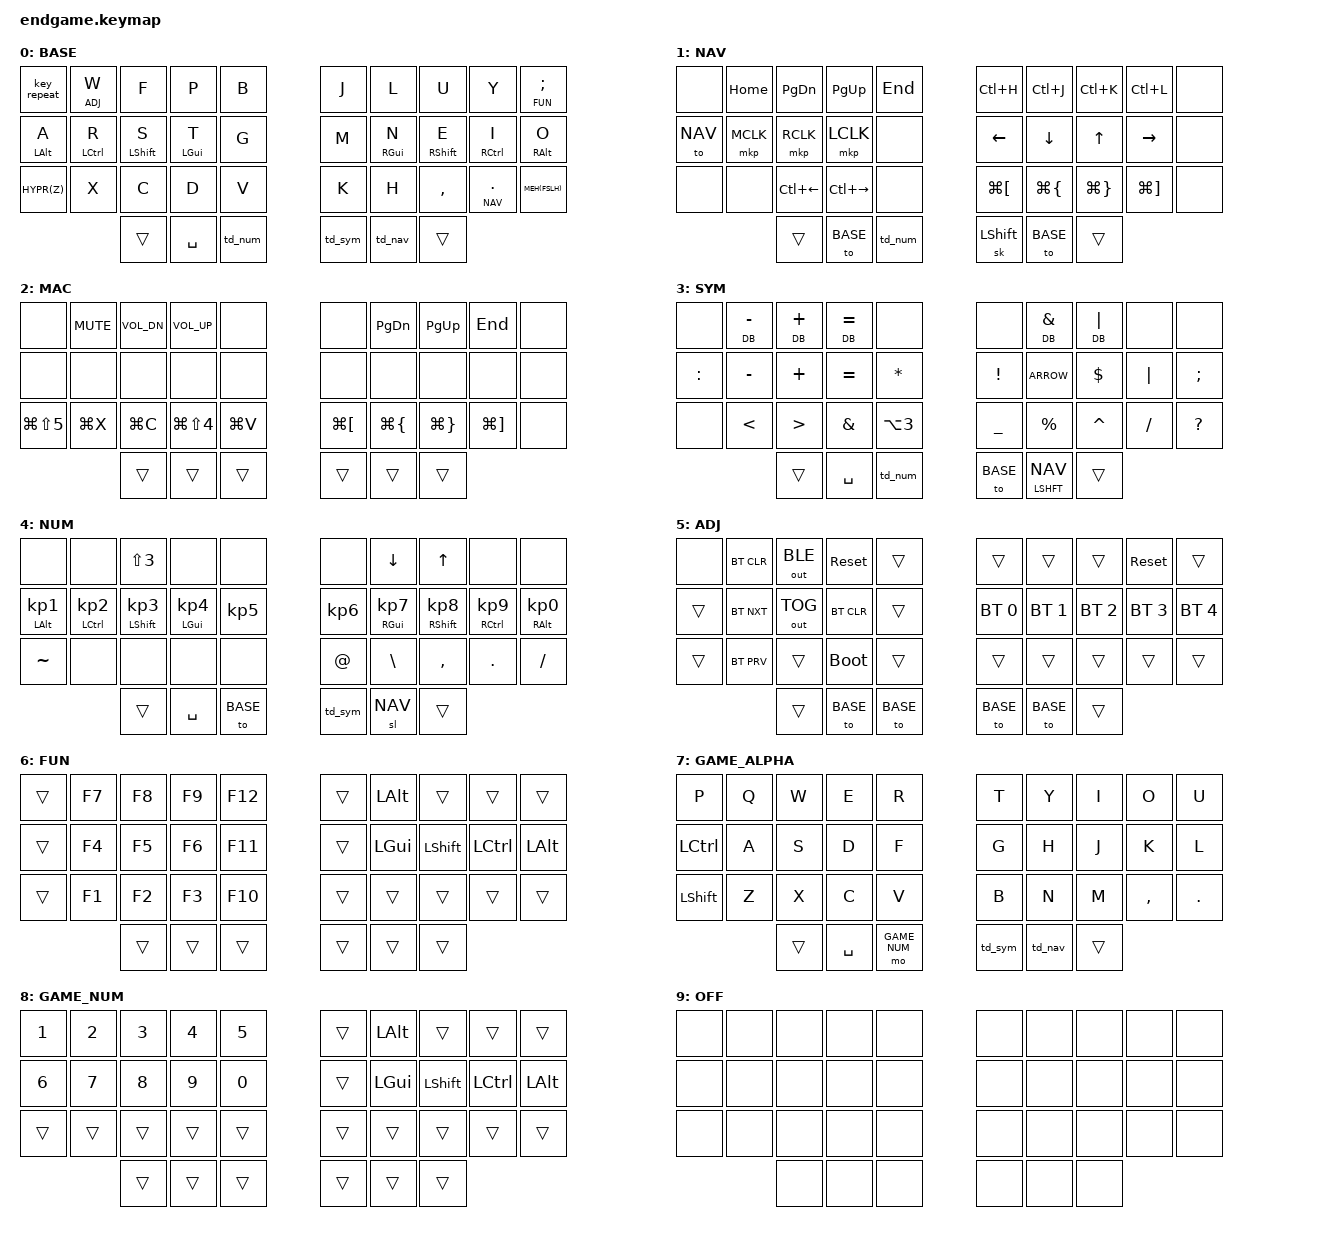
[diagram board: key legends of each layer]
#include <behaviors.dtsi>
#include <dt-bindings/zmk/keys.h>
#include <dt-bindings/zmk/bt.h>
#include <dt-bindings/zmk/outputs.h>
#include <dt-bindings/zmk/pointing.h>
#include <dt-bindings/zmk/ext_power.h>


  /**
   * Combos configuration: only on base layer.
   *
   * Combo key positions:
   *
   *    0  1  2  3  4    5  6  7  8  9
   *   10 11 12 13 14    15 16 17 18 19
   *   20 21 22 23 24    25 26 27 28 29
   *         30 31 32    33 34
   */




#define BASE 0
#define NAV  1
#define MAC  2
#define SYM  3
#define NUM  4
#define ADJ  5
#define FUN  6
#define GAME 7
#define GAME_NUM  8
#define OFF  9

#define HYPR(kc) &mt LC(LG(LS(LALT))) kc
#define MEH(kc) &mt LC(LS(LALT)) kc


&mt {
    tapping-term-ms = <201>;
    flavor = "tap-preferred";
 };
&sk {
     release-after-ms = <2000>;
     quick-release;
 };



/ {
        macros {

          ARROW: arrow {
            compatible = "zmk,behavior-macro";
            #binding-cells = <0>;
            wait-ms = <30>;
            bindings
                = <&kp EQUAL>
                , <&kp GT>
                ;
          };

          DB: double{
            compatible = "zmk,behavior-macro-one-param";
            #binding-cells = <1>;
            wait-ms = <30>;
            tap-ms = <40>;
            bindings
                = <&macro_param_1to1>
                , <&kp MACRO_PLACEHOLDER>
                , <&macro_param_1to1>
                , <&kp MACRO_PLACEHOLDER>
                ;
          };
        };

        combos {
            compatible = "zmk,combos";

            Game {
              timeout-ms = <30>;
              bindings = <&tog GAME>;
              key-positions = <0 1>;
            };

            Off {
              timeout-ms = <30>;
              bindings = <&tog OFF>;
              key-positions = <8 9>;
              layers = <BASE OFF>;
            };


            Escape  {
              timeout-ms = <30>;
              bindings = <&kp ESC>;
              key-positions = <11 12>;
            };

            Tab  {
              timeout-ms = <30>;
              bindings = <&kp TAB>;
              key-positions = <17 18>;
            };

            Enter  {
              timeout-ms = <30>;
              bindings = <&kp RET>;
              key-positions = <12 13>;
            };

            Enter2  {
              timeout-ms = <30>;
              bindings = <&kp RET>;
              key-positions = <16 17>;
            };

            Backspace  {
              timeout-ms = <30>;
              bindings = <&kp BSPC>;
              key-positions = <22 23>;
            };

            Backspace2  {
              timeout-ms = <30>;
              bindings = <&kp BSPC>;
              key-positions = <26 27>;
            };

            QCombo  {
              timeout-ms = <30>;
              bindings = <&kp Q>;
              key-positions = <1 2>;
              layers = <BASE>;
            };

            LPar  {
              timeout-ms = <30>;
              bindings = <&kp LPAR>;
              key-positions = <3 13>;
              layers = <BASE SYM NUM>;
            };

            RPar  {
              timeout-ms = <30>;
              bindings = <&kp RPAR>;
              key-positions = <6 16>;
            };

            LCurl  {
              timeout-ms = <30>;
              bindings = <&kp LBRC>;
              key-positions = <2 12>;
            };

            RCurl  {
              timeout-ms = <30>;
              bindings = <&kp RBRC>;
              key-positions = <7 17>;
            };

            LBracket  {
              timeout-ms = <30>;
              bindings = <&kp LBKT>;
              key-positions = <1 11>;
            };

            RBracket  {
              timeout-ms = <30>;
              bindings = <&kp RBKT>;
              key-positions = <8 18>;
            };


            LClick {
              timeout-ms = <30>;
              bindings = <&mkp MB1>;
              key-positions = <13 23>;
            };

            LClick2 {
              timeout-ms = <30>;
              bindings = <&mkp MB1>;
              key-positions = <2 3>;
            };

            LClickGame {
              timeout-ms = <30>;
              bindings = <&mkp MB1>;
              key-positions = <3 13>;
              layers = <GAME>;
            };

            RClickGame {
              timeout-ms = <30>;
              bindings = <&mkp MB2>;
              key-positions = <1 2>;
              layers = <GAME>;
            };

            MClickGame {
              timeout-ms = <30>;
              bindings = <&mkp MB3>;
              key-positions = <1 2 3>;
              layers = <GAME>;
            };

            RClick {
              timeout-ms = <30>;
              bindings = <&mkp MB2>;
              key-positions = <12 22>;
            };

            MClick  {
              timeout-ms = <30>;
              bindings = <&mkp MB3>;
              key-positions = <11 21>;
            };

            SingleQuote {
              timeout-ms = <30>;
              bindings = <&kp SQT>;
              key-positions = <16 26>;
            };

            DoubleQuote  {
              timeout-ms = <30>;
              bindings = <&kp DQT>;
              key-positions = <17 27>;
            };

            Grave  {
              timeout-ms = <30>;
              bindings = <&kp GRAVE>;
              key-positions = <18 28>;
            };

            MacroLayer  {
              timeout-ms = <30>;
              bindings = <&sl MAC>;
              key-positions = <7 8>;
            };

            CapsWord  {
              timeout-ms = <30>;
              bindings = <&caps_word>;
              key-positions = <27 28>;
            };

        };


       behaviors {
        nav: nav {
            compatible = "zmk,behavior-hold-tap";
            tapping-term-ms = <180>;
            flavor = "hold-preferred";
            #binding-cells = <2>;
            retro-tap;
            bindings = <&mo>, <&sk>;
        };
         td_num: num_layer_dance {
            compatible = "zmk,behavior-tap-dance";
            #binding-cells = <0>;
            tapping-term-ms = <200>;
            bindings = <&sl NUM>, <&to NUM>;
          };

       td_sym: sym_layer_dance {
            compatible = "zmk,behavior-tap-dance";
            #binding-cells = <0>;
            tapping-term-ms = <200>;
            bindings = <&sl SYM>, <&to SYM>;
          };
        td_nav: nav_layer {
            compatible = "zmk,behavior-tap-dance";
            #binding-cells = <0>;
            tapping-term-ms = <200>;
            bindings = <&nav NAV LSHFT>, <&caps_word>;
         };
        hm: homerow_mods {
            compatible = "zmk,behavior-hold-tap";
            #binding-cells = <2>;
            tapping-term-ms = <300>;
            quick-tap-ms = <250>;
            flavor = "tap-preferred";
            bindings = <&kp>, <&kp>;
        };
      hl: homerow_layers {
            compatible = "zmk,behavior-hold-tap";
            #binding-cells = <2>;
            tapping-term-ms = <220>;
            quick-tap-ms = <250>;
            flavor = "tap-preferred";
            bindings = <&mo>, <&kp>;
        };

       td: tapdance {
            compatible = "zmk,behavior-hold-tap";
            #binding-cells = <2>;
            tapping-term-ms = <190>;
            quick-tap-ms = <250>;
            flavor = "tap-preferred";
            bindings = <&kp>, <&kp>;
        };
     };

        keymap {
                compatible = "zmk,keymap";
// ▄▄▄▄▄▄▄▄▄▄▄▄▄▄▄▄▄▄▄▄▄▄▄▄▄▄▄▄▄▄▄▄▄▄▄▄▄▄▄▄▄▄▄▄▄▄▄▄▄▄▄▄▄▄▄▄▄▄▄▄▄▄▄▄▄▄▄▄▄▄▄▄▄▄▄▄▄▄▄▄▄▄▄▄▄▄▄▄▄▄▄▄▄▄▄▄▄▄▄▄▄▄▄▄▄▄▄▄▄▄▄▄▄▄▄▄▄▄▄▄▄▄▄▄▄▄▄▄▄▄▄▄▄▄▄▄▄▄▄▄▄▄▄▄▄▄▄▄▄

                base_layer {
// ┏━━━━━━━━━━━━━━━━━━━━━━━━━━━━━━━━━━━━━━━┓
label= "BASE"                              ;
// ┗━━━━━━━━━━━━━━━━━━━━━━━━━━━━━━━━━━━━━━━┛
//             ┏━━━━━━━━━━━┳━━━━━━━━━━━┳━━━━━━━━━━━┳━━━━━━━━━━━┳━━━━━━━━━━━┓   ┏━━━━━━━━━━━┳━━━━━━━━━━━┳━━━━━━━━━━━┳━━━━━━━━━━━┳━━━━━━━━━━━┓
//             ┃           ┃     W     ┃     F     ┃     P     ┃     B     ┃   ┃     J     ┃     L     ┃     U     ┃     Y     ┃           ┃
//             ┣━━━━━━━━━━━╋━━━━━━━━━━━╋━━━━━━━━━━━╋━━━━━━━━━━━╋━━━━━━━━━━━┫   ┣━━━━━━━━━━━╋━━━━━━━━━━━╋━━━━━━━━━━━╋━━━━━━━━━━━╋━━━━━━━━━━━┫
//             ┃     A     ┃     R     ┃     S     ┃     T     ┃     G     ┃   ┃     M     ┃     N     ┃     E     ┃     I     ┃     O     ┃
// ┏━━━━━━━━━━━╋━━━━━━━━━━━╋━━━━━━━━━━━╋━━━━━━━━━━━╋━━━━━━━━━━━╋━━━━━━━━━━━┫   ┣━━━━━━━━━━━╋━━━━━━━━━━━╋━━━━━━━━━━━╋━━━━━━━━━━━╋━━━━━━━━━━━╋━━━━━━━━━━━┓
// ┃     Q     ┃     Z     ┃     X     ┃     C     ┃     D     ┃     B     ┃   ┃     K     ┃     H     ┃     ,     ┃     .     ┃     /     ┃     ;     ┃
// ┗━━━━━━━━━━━┻━━━━━━━━━━━┻━━━━━━━━━━━╋━━━━━━━━━━━╋━━━━━━━━━━━╋━━━━━━━━━━━┫   ┣━━━━━━━━━━━╋━━━━━━━━━━━╋━━━━━━━━━━━╋━━━━━━━━━━━┻━━━━━━━━━━━┻━━━━━━━━━━━┛
//                                     ┃           ┃    SYM    ┃   SPACE   ┃   ┃   LSHFT   ┃    NUM    ┃           ┃
//                                     ┗━━━━━━━━━━━┻━━━━━━━━━━━┻━━━━━━━━━━━┛   ┗━━━━━━━━━━━┻━━━━━━━━━━━┻━━━━━━━━━━━┛
 bindings = <
// ╷           ╷           ╷           ╷           ╷           ╷           ╷   ╷           ╷           ╷           ╷           ╷           ╷           ╷

                &key_repeat   &lt ADJ W      &kp F         &kp P        &kp B           &kp J       &kp L          &kp U         &kp Y          &lt FUN SEMI
                &hm LALT A    &hm LCTRL R    &hm LSHFT S   &hm LGUI T   &kp G           &kp M       &hm RGUI N     &hm RSHFT E   &hm RCTRL I    &hm RALT O
                HYPR(Z)       &kp X          &kp C         &kp D        &kp V           &kp K       &kp H          &kp COMMA     &lt NAV DOT    MEH(FSLH)
                                             &trans        &kp SPACE    &td_num         &td_sym     &td_nav        &trans
                        >;
                };

// ▄▄▄▄▄▄▄▄▄▄▄▄▄▄▄▄▄▄▄▄▄▄▄▄▄▄▄▄▄▄▄▄▄▄▄▄▄▄▄▄▄▄▄▄▄▄▄▄▄▄▄▄▄▄▄▄▄▄▄▄▄▄▄▄▄▄▄▄▄▄▄▄▄▄▄▄▄▄▄▄▄▄▄▄▄▄▄▄▄▄▄▄▄▄▄▄▄▄▄▄▄▄▄▄▄▄▄▄▄▄▄▄▄▄▄▄▄▄▄▄▄▄▄▄▄▄▄▄▄▄▄▄▄▄▄▄▄▄▄▄▄▄▄▄▄▄▄▄▄


                nav_layer {
// ┏━━━━━━━━━━━━━━━━━━━━━━━━━━━━━━━━━━━━━━━┓
label= "NAV"                               ;
// ┗━━━━━━━━━━━━━━━━━━━━━━━━━━━━━━━━━━━━━━━┛
//             ┏━━━━━━━━━━━┳━━━━━━━━━━━┳━━━━━━━━━━━┳━━━━━━━━━━━┳━━━━━━━━━━━┓   ┏━━━━━━━━━━━┳━━━━━━━━━━━┳━━━━━━━━━━━┳━━━━━━━━━━━┳━━━━━━━━━━━┓
//             ┃           ┃   HOME    ┃  P DOWN   ┃    P UP   ┃    END    ┃   ┃           ┃           ┃           ┃           ┃           ┃
//             ┣━━━━━━━━━━━╋━━━━━━━━━━━╋━━━━━━━━━━━╋━━━━━━━━━━━╋━━━━━━━━━━━┫   ┣━━━━━━━━━━━╋━━━━━━━━━━━╋━━━━━━━━━━━╋━━━━━━━━━━━╋━━━━━━━━━━━┫
//             ┃    NAV    ┃    MCLK   ┃    RCLK   ┃    LCLK   ┃           ┃   ┃   LEFT    ┃   DOWN    ┃     UP    ┃   RIGHT   ┃           ┃
// ┏━━━━━━━━━━━╋━━━━━━━━━━━╋━━━━━━━━━━━╋━━━━━━━━━━━╋━━━━━━━━━━━╋━━━━━━━━━━━┫   ┣━━━━━━━━━━━╋━━━━━━━━━━━╋━━━━━━━━━━━╋━━━━━━━━━━━╋━━━━━━━━━━━╋━━━━━━━━━━━┓
// ┃           ┃           ┃           ┃  SPACE L  ┃  SPACE R  ┃           ┃   ┃   BACK    ┃   P TAB   ┃   N TAB   ┃    FOR    ┃           ┃           ┃
// ┗━━━━━━━━━━━┻━━━━━━━━━━━┻━━━━━━━━━━━╋━━━━━━━━━━━╋━━━━━━━━━━━╋━━━━━━━━━━━┫   ┣━━━━━━━━━━━╋━━━━━━━━━━━╋━━━━━━━━━━━╋━━━━━━━━━━━┻━━━━━━━━━━━┻━━━━━━━━━━━┛
//                                     ┃           ┃    SYM    ┃   SPACE   ┃   ┃   LSHFT   ┃   BASE    ┃           ┃
//                                     ┗━━━━━━━━━━━┻━━━━━━━━━━━┻━━━━━━━━━━━┛   ┗━━━━━━━━━━━┻━━━━━━━━━━━┻━━━━━━━━━━━┛
 bindings = <
// ╷           ╷           ╷           ╷           ╷           ╷           ╷   ╷           ╷           ╷           ╷           ╷           ╷           ╷

                &none    &kp HOME     &kp PG_DN      &kp PG_UP     &kp END             &kp LC(H)     &kp LC(J)      &kp LC(K)      &kp LC(L)     &none
                &to NAV  &mkp MCLK    &mkp RCLK      &mkp LCLK     &none               &kp LEFT      &kp DOWN       &kp UP         &kp RIGHT     &none
                &none    &none        &kp LC(LEFT)   &kp LC(RIGHT) &none               &kp LG(LBKT)  &kp LG(LBRC)   &kp LG(RBRC)   &kp LG(RBKT)  &none
                                      &trans         &to BASE      &td_num             &sk LSHFT     &to BASE       &trans
                        >;
                };

                macro_layer {
// ┏━━━━━━━━━━━━━━━━━━━━━━━━━━━━━━━━━━━━━━━┓
label= "MAC"                               ;
// ┗━━━━━━━━━━━━━━━━━━━━━━━━━━━━━━━━━━━━━━━┛
//             ┏━━━━━━━━━━━┳━━━━━━━━━━━┳━━━━━━━━━━━┳━━━━━━━━━━━┳━━━━━━━━━━━┓   ┏━━━━━━━━━━━┳━━━━━━━━━━━┳━━━━━━━━━━━┳━━━━━━━━━━━┳━━━━━━━━━━━┓
//             ┃           ┃    MUTE   ┃  V DOWN   ┃   V UP    ┃           ┃   ┃           ┃           ┃           ┃           ┃           ┃
//             ┣━━━━━━━━━━━╋━━━━━━━━━━━╋━━━━━━━━━━━╋━━━━━━━━━━━╋━━━━━━━━━━━┫   ┣━━━━━━━━━━━╋━━━━━━━━━━━╋━━━━━━━━━━━╋━━━━━━━━━━━╋━━━━━━━━━━━┫
//             ┃           ┃           ┃           ┃           ┃           ┃   ┃           ┃           ┃           ┃           ┃           ┃
// ┏━━━━━━━━━━━╋━━━━━━━━━━━╋━━━━━━━━━━━╋━━━━━━━━━━━╋━━━━━━━━━━━╋━━━━━━━━━━━┫   ┣━━━━━━━━━━━╋━━━━━━━━━━━╋━━━━━━━━━━━╋━━━━━━━━━━━╋━━━━━━━━━━━╋━━━━━━━━━━━┓
// ┃           ┃   SCNREC  ┃    CUT    ┃    COPY   ┃   SCNSHT  ┃   PASTE   ┃   ┃           ┃           ┃           ┃           ┃           ┃           ┃
// ┗━━━━━━━━━━━┻━━━━━━━━━━━┻━━━━━━━━━━━╋━━━━━━━━━━━╋━━━━━━━━━━━╋━━━━━━━━━━━┫   ┣━━━━━━━━━━━╋━━━━━━━━━━━╋━━━━━━━━━━━╋━━━━━━━━━━━┻━━━━━━━━━━━┻━━━━━━━━━━━┛
//                                     ┃           ┃    SYM    ┃   SPACE   ┃   ┃   LSHFT   ┃    NUM    ┃           ┃
//                                     ┗━━━━━━━━━━━┻━━━━━━━━━━━┻━━━━━━━━━━━┛   ┗━━━━━━━━━━━┻━━━━━━━━━━━┻━━━━━━━━━━━┛
 bindings = <
// ╷           ╷           ╷           ╷           ╷           ╷           ╷   ╷           ╷           ╷           ╷           ╷           ╷           ╷

                &none                 &kp C_MUTE   &kp C_VOL_DN  &kp C_VOL_UP         &none                  &none         &kp PG_DN      &kp PG_UP      &kp END       &none
                &none                 &none        &none         &none                &none                  &none         &none          &none          &none         &none
                &kp LG(LS(NUMBER_5))  &kp LG(X)    &kp LG(C)     &kp LG(LS(NUMBER_4)) &kp LG(V)              &kp LG(LBKT)  &kp LG(LBRC)   &kp LG(RBRC)   &kp LG(RBKT)  &none
                                                   &trans       &trans                &trans      &trans      &trans        &trans
                        >;
                };
// ▄▄▄▄▄▄▄▄▄▄▄▄▄▄▄▄▄▄▄▄▄▄▄▄▄▄▄▄▄▄▄▄▄▄▄▄▄▄▄▄▄▄▄▄▄▄▄▄▄▄▄▄▄▄▄▄▄▄▄▄▄▄▄▄▄▄▄▄▄▄▄▄▄▄▄▄▄▄▄▄▄▄▄▄▄▄▄▄▄▄▄▄▄▄▄▄▄▄▄▄▄▄▄▄▄▄▄▄▄▄▄▄▄▄▄▄▄▄▄▄▄▄▄▄▄▄▄▄▄▄▄▄▄▄▄▄▄▄▄▄▄▄▄▄▄▄▄▄▄


                sym_layer {
// ┏━━━━━━━━━━━━━━━━━━━━━━━━━━━━━━━━━━━━━━━┓
label= "SYM"                               ;
// ┗━━━━━━━━━━━━━━━━━━━━━━━━━━━━━━━━━━━━━━━┛
//             ┏━━━━━━━━━━━┳━━━━━━━━━━━┳━━━━━━━━━━━┳━━━━━━━━━━━┳━━━━━━━━━━━┓   ┏━━━━━━━━━━━┳━━━━━━━━━━━┳━━━━━━━━━━━┳━━━━━━━━━━━┳━━━━━━━━━━━┓
//             ┃           ┃     --    ┃     ++    ┃     ==    ┃           ┃   ┃           ┃     &&    ┃           ┃    ||     ┃           ┃
//             ┣━━━━━━━━━━━╋━━━━━━━━━━━╋━━━━━━━━━━━╋━━━━━━━━━━━╋━━━━━━━━━━━┫   ┣━━━━━━━━━━━╋━━━━━━━━━━━╋━━━━━━━━━━━╋━━━━━━━━━━━╋━━━━━━━━━━━┫
//             ┃     :     ┃     -     ┃     +     ┃     =     ┃     *     ┃   ┃     !     ┃     =>    ┃     $     ┃     |     ┃     ;     ┃
// ┏━━━━━━━━━━━╋━━━━━━━━━━━╋━━━━━━━━━━━╋━━━━━━━━━━━╋━━━━━━━━━━━╋━━━━━━━━━━━┫   ┣━━━━━━━━━━━╋━━━━━━━━━━━╋━━━━━━━━━━━╋━━━━━━━━━━━╋━━━━━━━━━━━╋━━━━━━━━━━━┓
// ┃           ┃           ┃     <     ┃     >     ┃     &     ┃     #     ┃   ┃     _     ┃     %     ┃     ^     ┃     /     ┃     ?     ┃           ┃
// ┗━━━━━━━━━━━┻━━━━━━━━━━━┻━━━━━━━━━━━╋━━━━━━━━━━━╋━━━━━━━━━━━╋━━━━━━━━━━━┫   ┣━━━━━━━━━━━╋━━━━━━━━━━━╋━━━━━━━━━━━╋━━━━━━━━━━━┻━━━━━━━━━━━┻━━━━━━━━━━━┛
//                                     ┃           ┃    BASE   ┃   SPACE   ┃   ┃   LSHFT   ┃    NUM    ┃           ┃
//                                     ┗━━━━━━━━━━━┻━━━━━━━━━━━┻━━━━━━━━━━━┛   ┗━━━━━━━━━━━┻━━━━━━━━━━━┻━━━━━━━━━━━┛
 bindings = <
// ╷           ╷           ╷           ╷           ╷           ╷           ╷   ╷           ╷           ╷           ╷           ╷           ╷           ╷

                &none       &DB MINUS       &DB PLUS    &DB EQUAL   &none                 &none       &DB AMPS    &DB PIPE    &none       &none
                &kp COLON   &kp MINUS       &kp PLUS    &kp EQUAL   &kp STAR              &kp EXCL    &ARROW      &kp DLLR    &kp PIPE    &kp SEMI
                &none       &kp LT          &kp GT      &kp AMPS    &kp LA(NUMBER_3)      &kp UNDER   &kp PRCNT   &kp CARET   &kp FSLH    &kp QMARK
                                            &trans      &kp SPACE   &td_num               &to BASE    &nav LSHFT NAV    &trans
                        >;
                };

// ▄▄▄▄▄▄▄▄▄▄▄▄▄▄▄▄▄▄▄▄▄▄▄▄▄▄▄▄▄▄▄▄▄▄▄▄▄▄▄▄▄▄▄▄▄▄▄▄▄▄▄▄▄▄▄▄▄▄▄▄▄▄▄▄▄▄▄▄▄▄▄▄▄▄▄▄▄▄▄▄▄▄▄▄▄▄▄▄▄▄▄▄▄▄▄▄▄▄▄▄▄▄▄▄▄▄▄▄▄▄▄▄▄▄▄▄▄▄▄▄▄▄▄▄▄▄▄▄▄▄▄▄▄▄▄▄▄▄▄▄▄▄▄▄▄▄▄▄▄

                num_layer {
// ┏━━━━━━━━━━━━━━━━━━━━━━━━━━━━━━━━━━━━━━━┓
label= "NUM"                               ;
// ┗━━━━━━━━━━━━━━━━━━━━━━━━━━━━━━━━━━━━━━━┛
//             ┏━━━━━━━━━━━┳━━━━━━━━━━━┳━━━━━━━━━━━┳━━━━━━━━━━━┳━━━━━━━━━━━┓   ┏━━━━━━━━━━━┳━━━━━━━━━━━┳━━━━━━━━━━━┳━━━━━━━━━━━┳━━━━━━━━━━━┓
//             ┃           ┃           ┃     £     ┃           ┃           ┃   ┃           ┃           ┃           ┃           ┃           ┃
//             ┣━━━━━━━━━━━╋━━━━━━━━━━━╋━━━━━━━━━━━╋━━━━━━━━━━━╋━━━━━━━━━━━┫   ┣━━━━━━━━━━━╋━━━━━━━━━━━╋━━━━━━━━━━━╋━━━━━━━━━━━╋━━━━━━━━━━━┫
//             ┃     1     ┃     2     ┃     3     ┃     4     ┃     5     ┃   ┃     6     ┃     7     ┃     8     ┃     9     ┃     0     ┃
// ┏━━━━━━━━━━━╋━━━━━━━━━━━╋━━━━━━━━━━━╋━━━━━━━━━━━╋━━━━━━━━━━━╋━━━━━━━━━━━┫   ┣━━━━━━━━━━━╋━━━━━━━━━━━╋━━━━━━━━━━━╋━━━━━━━━━━━╋━━━━━━━━━━━╋━━━━━━━━━━━┓
// ┃           ┃     ~     ┃           ┃           ┃           ┃           ┃   ┃     @     ┃     \     ┃     ,     ┃     .     ┃     /     ┃           ┃
// ┗━━━━━━━━━━━┻━━━━━━━━━━━┻━━━━━━━━━━━╋━━━━━━━━━━━╋━━━━━━━━━━━╋━━━━━━━━━━━┫   ┣━━━━━━━━━━━╋━━━━━━━━━━━╋━━━━━━━━━━━╋━━━━━━━━━━━┻━━━━━━━━━━━┻━━━━━━━━━━━┛
//                                     ┃           ┃   SPACE   ┃    SYM    ┃   ┃   LSHFT   ┃    BASE   ┃           ┃
//                                     ┗━━━━━━━━━━━┻━━━━━━━━━━━┻━━━━━━━━━━━┛   ┗━━━━━━━━━━━┻━━━━━━━━━━━┻━━━━━━━━━━━┛
 bindings = <
// ╷           ╷           ╷           ╷           ╷           ╷           ╷   ╷           ╷           ╷           ╷           ╷           ╷           ╷

                &none                  &none              &kp LS(NUMBER_3)   &none              &none                 &none           &kp DOWN           &kp UP             &none              &none
                &hm LALT KP_N1         &hm LCTRL KP_N2    &hm LSHFT KP_N3    &hm LGUI KP_N4     &kp KP_N5             &kp KP_N6       &hm RGUI KP_N7     &hm RSHFT KP_N8   &hm RCTRL KP_N9    &hm RALT KP_N0
                &kp TILDE              &none              &none              &none              &none                 &kp AT          &kp BSLH           &kp COMMA         &kp DOT            &kp FSLH
                                                          &trans            &kp SPACE          &to BASE               &td_sym         &sl NAV            &trans
                        >;
                };

// ▄▄▄▄▄▄▄▄▄▄▄▄▄▄▄▄▄▄▄▄▄▄▄▄▄▄▄▄▄▄▄▄▄▄▄▄▄▄▄▄▄▄▄▄▄▄▄▄▄▄▄▄▄▄▄▄▄▄▄▄▄▄▄▄▄▄▄▄▄▄▄▄▄▄▄▄▄▄▄▄▄▄▄▄▄▄▄▄▄▄▄▄▄▄▄▄▄▄▄▄▄▄▄▄▄▄▄▄▄▄▄▄▄▄▄▄▄▄▄▄▄▄▄▄▄▄▄▄▄▄▄▄▄▄▄▄▄▄▄▄▄▄▄▄▄▄▄▄▄



                adjust_layer {
// ┏━━━━━━━━━━━━━━━━━━━━━━━━━━━━━━━━━━━━━━━┓
label= "ADJ"                               ;
// ┗━━━━━━━━━━━━━━━━━━━━━━━━━━━━━━━━━━━━━━━┛
//             ┏━━━━━━━━━━━┳━━━━━━━━━━━┳━━━━━━━━━━━┳━━━━━━━━━━━┳━━━━━━━━━━━┓   ┏━━━━━━━━━━━┳━━━━━━━━━━━┳━━━━━━━━━━━┳━━━━━━━━━━━┳━━━━━━━━━━━┓
//             ┃           ┃ BT CLEAR  ┃  OUT BLE  ┃   RESET   ┃           ┃   ┃           ┃           ┃           ┃   RESET   ┃           ┃
//             ┣━━━━━━━━━━━╋━━━━━━━━━━━╋━━━━━━━━━━━╋━━━━━━━━━━━╋━━━━━━━━━━━┫   ┣━━━━━━━━━━━╋━━━━━━━━━━━╋━━━━━━━━━━━╋━━━━━━━━━━━╋━━━━━━━━━━━┫
//             ┃           ┃ BT NEXT   ┃  OUT TOG  ┃  BT CLEAR ┃           ┃   ┃    BT 1   ┃    BT 2   ┃   BT 3    ┃    BT 4   ┃   BT 5    ┃
// ┏━━━━━━━━━━━╋━━━━━━━━━━━╋━━━━━━━━━━━╋━━━━━━━━━━━╋━━━━━━━━━━━╋━━━━━━━━━━━┫   ┣━━━━━━━━━━━╋━━━━━━━━━━━╋━━━━━━━━━━━╋━━━━━━━━━━━╋━━━━━━━━━━━╋━━━━━━━━━━━┓
// ┃           ┃           ┃ BT PREV   ┃           ┃  BOOTLOAD ┃           ┃   ┃           ┃           ┃           ┃           ┃           ┃           ┃
// ┗━━━━━━━━━━━┻━━━━━━━━━━━┻━━━━━━━━━━━╋━━━━━━━━━━━╋━━━━━━━━━━━╋━━━━━━━━━━━┫   ┣━━━━━━━━━━━╋━━━━━━━━━━━╋━━━━━━━━━━━╋━━━━━━━━━━━┻━━━━━━━━━━━┻━━━━━━━━━━━┛
//                                     ┃           ┃           ┃           ┃   ┃           ┃           ┃           ┃
//                                     ┗━━━━━━━━━━━┻━━━━━━━━━━━┻━━━━━━━━━━━┛   ┗━━━━━━━━━━━┻━━━━━━━━━━━┻━━━━━━━━━━━┛
 bindings = <
// ╷           ╷           ╷           ╷           ╷           ╷           ╷   ╷           ╷           ╷           ╷           ╷           ╷           ╷

                &none       &bt BT_CLR  &out OUT_BLE    &sys_reset    &trans          &trans          &trans          &trans          &sys_reset      &trans
                &trans      &bt BT_NXT  &out OUT_TOG    &bt BT_CLR    &trans          &bt BT_SEL 0    &bt BT_SEL 1    &bt BT_SEL 2    &bt BT_SEL 3    &bt BT_SEL 4
                &trans      &bt BT_PRV  &trans          &bootloader   &trans          &trans          &trans          &trans          &trans          &trans
                                        &trans          &to BASE      &to BASE        &to BASE        &to BASE        &trans
                        >;
                };

// ▄▄▄▄▄▄▄▄▄▄▄▄▄▄▄▄▄▄▄▄▄▄▄▄▄▄▄▄▄▄▄▄▄▄▄▄▄▄▄▄▄▄▄▄▄▄▄▄▄▄▄▄▄▄▄▄▄▄▄▄▄▄▄▄▄▄▄▄▄▄▄▄▄▄▄▄▄▄▄▄▄▄▄▄▄▄▄▄▄▄▄▄▄▄▄▄▄▄▄▄▄▄▄▄▄▄▄▄▄▄▄▄▄▄▄▄▄▄▄▄▄▄▄▄▄▄▄▄▄▄▄▄▄▄▄▄▄▄▄▄▄▄▄▄▄▄▄▄▄


                fun_layer {
// ┏━━━━━━━━━━━━━━━━━━━━━━━━━━━━━━━━━━━━━━━┓
label= "FUN"                              ;
// ┗━━━━━━━━━━━━━━━━━━━━━━━━━━━━━━━━━━━━━━━┛
//             ┏━━━━━━━━━━━┳━━━━━━━━━━━┳━━━━━━━━━━━┳━━━━━━━━━━━┳━━━━━━━━━━━┓   ┏━━━━━━━━━━━┳━━━━━━━━━━━┳━━━━━━━━━━━┳━━━━━━━━━━━┳━━━━━━━━━━━┓
//             ┃           ┃    F7     ┃     F8    ┃    F9     ┃    F12    ┃   ┃           ┃    OPT    ┃           ┃           ┃           ┃
//             ┣━━━━━━━━━━━╋━━━━━━━━━━━╋━━━━━━━━━━━╋━━━━━━━━━━━╋━━━━━━━━━━━┫   ┣━━━━━━━━━━━╋━━━━━━━━━━━╋━━━━━━━━━━━╋━━━━━━━━━━━╋━━━━━━━━━━━┫
//             ┃           ┃    F4     ┃     F5    ┃    F6     ┃    F11    ┃   ┃           ┃    GUI    ┃   SHFT    ┃    CTRL   ┃    OPT    ┃
// ┏━━━━━━━━━━━╋━━━━━━━━━━━╋━━━━━━━━━━━╋━━━━━━━━━━━╋━━━━━━━━━━━╋━━━━━━━━━━━┫   ┣━━━━━━━━━━━╋━━━━━━━━━━━╋━━━━━━━━━━━╋━━━━━━━━━━━╋━━━━━━━━━━━╋━━━━━━━━━━━┓
// ┃    ESC    ┃           ┃    F1     ┃     F2    ┃    F3     ┃    F10    ┃   ┃           ┃           ┃           ┃           ┃           ┃    TAB    ┃
// ┗━━━━━━━━━━━┻━━━━━━━━━━━┻━━━━━━━━━━━╋━━━━━━━━━━━╋━━━━━━━━━━━╋━━━━━━━━━━━┫   ┣━━━━━━━━━━━╋━━━━━━━━━━━╋━━━━━━━━━━━╋━━━━━━━━━━━┻━━━━━━━━━━━┻━━━━━━━━━━━┛
//                                     ┃           ┃           ┃           ┃   ┃           ┃           ┃           ┃
//                                     ┗━━━━━━━━━━━┻━━━━━━━━━━━┻━━━━━━━━━━━┛   ┗━━━━━━━━━━━┻━━━━━━━━━━━┻━━━━━━━━━━━┛
 bindings = <
// ╷           ╷           ╷           ╷           ╷           ╷           ╷   ╷           ╷           ╷           ╷           ╷           ╷           ╷

                &trans      &kp F7      &kp F8      &kp F9      &kp F12         &trans      &kp LALT    &trans      &trans        &trans
                &trans      &kp F4      &kp F5      &kp F6      &kp F11         &trans      &kp LGUI    &kp LSHFT   &kp LCTRL     &kp LALT
                &trans      &kp F1      &kp F2      &kp F3      &kp F10         &trans      &trans      &trans      &trans        &trans
                                        &trans      &trans      &trans          &trans      &trans      &trans
                        >;
                };

// ▄▄▄▄▄▄▄▄▄▄▄▄▄▄▄▄▄▄▄▄▄▄▄▄▄▄▄▄▄▄▄▄▄▄▄▄▄▄▄▄▄▄▄▄▄▄▄▄▄▄▄▄▄▄▄▄▄▄▄▄▄▄▄▄▄▄▄▄▄▄▄▄▄▄▄▄▄▄▄▄▄▄▄▄▄▄▄▄▄▄▄▄▄▄▄▄▄▄▄▄▄▄▄▄▄▄▄▄▄▄▄▄▄▄▄▄▄▄▄▄▄▄▄▄▄▄▄▄▄▄▄▄▄▄▄▄▄▄▄▄▄▄▄▄▄▄▄▄▄


                gaming_alpha {
// ┏━━━━━━━━━━━━━━━━━━━━━━━━━━━━━━━━━━━━━━━┓
label= "GAME_ALPHA"                              ;
// ┗━━━━━━━━━━━━━━━━━━━━━━━━━━━━━━━━━━━━━━━┛
//             ┏━━━━━━━━━━━┳━━━━━━━━━━━┳━━━━━━━━━━━┳━━━━━━━━━━━┳━━━━━━━━━━━┓   ┏━━━━━━━━━━━┳━━━━━━━━━━━┳━━━━━━━━━━━┳━━━━━━━━━━━┳━━━━━━━━━━━┓
//             ┃           ┃    F7     ┃     F8    ┃    F9     ┃    F12    ┃   ┃           ┃    OPT    ┃           ┃           ┃           ┃
//             ┣━━━━━━━━━━━╋━━━━━━━━━━━╋━━━━━━━━━━━╋━━━━━━━━━━━╋━━━━━━━━━━━┫   ┣━━━━━━━━━━━╋━━━━━━━━━━━╋━━━━━━━━━━━╋━━━━━━━━━━━╋━━━━━━━━━━━┫
//             ┃           ┃    F4     ┃     F5    ┃    F6     ┃    F11    ┃   ┃           ┃    GUI    ┃   SHFT    ┃    CTRL   ┃    OPT    ┃
// ┏━━━━━━━━━━━╋━━━━━━━━━━━╋━━━━━━━━━━━╋━━━━━━━━━━━╋━━━━━━━━━━━╋━━━━━━━━━━━┫   ┣━━━━━━━━━━━╋━━━━━━━━━━━╋━━━━━━━━━━━╋━━━━━━━━━━━╋━━━━━━━━━━━╋━━━━━━━━━━━┓
// ┃    ESC    ┃           ┃    F1     ┃     F2    ┃    F3     ┃    F10    ┃   ┃           ┃           ┃           ┃           ┃           ┃    TAB    ┃
// ┗━━━━━━━━━━━┻━━━━━━━━━━━┻━━━━━━━━━━━╋━━━━━━━━━━━╋━━━━━━━━━━━╋━━━━━━━━━━━┫   ┣━━━━━━━━━━━╋━━━━━━━━━━━╋━━━━━━━━━━━╋━━━━━━━━━━━┻━━━━━━━━━━━┻━━━━━━━━━━━┛
//                                     ┃           ┃           ┃           ┃   ┃           ┃           ┃           ┃
//                                     ┗━━━━━━━━━━━┻━━━━━━━━━━━┻━━━━━━━━━━━┛   ┗━━━━━━━━━━━┻━━━━━━━━━━━┻━━━━━━━━━━━┛
 bindings = <
// ╷           ╷           ╷           ╷           ╷           ╷           ╷   ╷           ╷           ╷           ╷           ╷           ╷           ╷

                &kp P      &kp Q         &kp W      &kp E         &kp R            &kp T           &kp Y       &kp I          &kp O         &kp U
                &kp LCTRL  &kp A         &kp S      &kp D         &kp F            &kp G           &kp H       &kp J          &kp K         &kp L
                &kp LSHFT  &kp Z         &kp X      &kp C         &kp V            &kp B           &kp N       &kp M          &kp COMMA     &kp DOT
                                         &trans     &kp SPACE     &mo GAME_NUM     &td_sym         &td_nav     &trans
                        >;
                };

// ▄▄▄▄▄▄▄▄▄▄▄▄▄▄▄▄▄▄▄▄▄▄▄▄▄▄▄▄▄▄▄▄▄▄▄▄▄▄▄▄▄▄▄▄▄▄▄▄▄▄▄▄▄▄▄▄▄▄▄▄▄▄▄▄▄▄▄▄▄▄▄▄▄▄▄▄▄▄▄▄▄▄▄▄▄▄▄▄▄▄▄▄▄▄▄▄▄▄▄▄▄▄▄▄▄▄▄▄▄▄▄▄▄▄▄▄▄▄▄▄▄▄▄▄▄▄▄▄▄▄▄▄▄▄▄▄▄▄▄▄▄▄▄▄▄▄▄▄▄


                gaming_num {
// ┏━━━━━━━━━━━━━━━━━━━━━━━━━━━━━━━━━━━━━━━┓
label= "GAME_NUM"                              ;
// ┗━━━━━━━━━━━━━━━━━━━━━━━━━━━━━━━━━━━━━━━┛
//             ┏━━━━━━━━━━━┳━━━━━━━━━━━┳━━━━━━━━━━━┳━━━━━━━━━━━┳━━━━━━━━━━━┓   ┏━━━━━━━━━━━┳━━━━━━━━━━━┳━━━━━━━━━━━┳━━━━━━━━━━━┳━━━━━━━━━━━┓
//             ┃           ┃    F7     ┃     F8    ┃    F9     ┃    F12    ┃   ┃           ┃    OPT    ┃           ┃           ┃           ┃
//             ┣━━━━━━━━━━━╋━━━━━━━━━━━╋━━━━━━━━━━━╋━━━━━━━━━━━╋━━━━━━━━━━━┫   ┣━━━━━━━━━━━╋━━━━━━━━━━━╋━━━━━━━━━━━╋━━━━━━━━━━━╋━━━━━━━━━━━┫
//             ┃           ┃    F4     ┃     F5    ┃    F6     ┃    F11    ┃   ┃           ┃    GUI    ┃   SHFT    ┃    CTRL   ┃    OPT    ┃
// ┏━━━━━━━━━━━╋━━━━━━━━━━━╋━━━━━━━━━━━╋━━━━━━━━━━━╋━━━━━━━━━━━╋━━━━━━━━━━━┫   ┣━━━━━━━━━━━╋━━━━━━━━━━━╋━━━━━━━━━━━╋━━━━━━━━━━━╋━━━━━━━━━━━╋━━━━━━━━━━━┓
// ┃    ESC    ┃           ┃    F1     ┃     F2    ┃    F3     ┃    F10    ┃   ┃           ┃           ┃           ┃           ┃           ┃    TAB    ┃
// ┗━━━━━━━━━━━┻━━━━━━━━━━━┻━━━━━━━━━━━╋━━━━━━━━━━━╋━━━━━━━━━━━╋━━━━━━━━━━━┫   ┣━━━━━━━━━━━╋━━━━━━━━━━━╋━━━━━━━━━━━╋━━━━━━━━━━━┻━━━━━━━━━━━┻━━━━━━━━━━━┛
//                                     ┃           ┃           ┃           ┃   ┃           ┃           ┃           ┃
//                                     ┗━━━━━━━━━━━┻━━━━━━━━━━━┻━━━━━━━━━━━┛   ┗━━━━━━━━━━━┻━━━━━━━━━━━┻━━━━━━━━━━━┛
 bindings = <
// ╷           ╷           ╷           ╷           ╷           ╷           ╷   ╷           ╷           ╷           ╷           ╷           ╷           ╷

                &kp N1      &kp N2      &kp N3      &kp N4      &kp N5       &trans      &kp LALT    &trans      &trans        &trans
                &kp N6      &kp N7      &kp N8      &kp N9      &kp N0       &trans      &kp LGUI    &kp LSHFT   &kp LCTRL     &kp LALT
                &trans      &trans      &trans      &trans      &trans       &trans      &trans      &trans      &trans        &trans
                                        &trans      &trans      &trans       &trans      &trans         &trans
                        >;
                };

                off_layer {
// ┏━━━━━━━━━━━━━━━━━━━━━━━━━━━━━━━━━━━━━━━┓
label= "OFF"                              ;
// ┗━━━━━━━━━━━━━━━━━━━━━━━━━━━━━━━━━━━━━━━┛
//             ┏━━━━━━━━━━━┳━━━━━━━━━━━┳━━━━━━━━━━━┳━━━━━━━━━━━┳━━━━━━━━━━━┓   ┏━━━━━━━━━━━┳━━━━━━━━━━━┳━━━━━━━━━━━┳━━━━━━━━━━━┳━━━━━━━━━━━┓
//             ┃           ┃    F7     ┃     F8    ┃    F9     ┃    F12    ┃   ┃           ┃    OPT    ┃           ┃           ┃           ┃
//             ┣━━━━━━━━━━━╋━━━━━━━━━━━╋━━━━━━━━━━━╋━━━━━━━━━━━╋━━━━━━━━━━━┫   ┣━━━━━━━━━━━╋━━━━━━━━━━━╋━━━━━━━━━━━╋━━━━━━━━━━━╋━━━━━━━━━━━┫
//             ┃           ┃    F4     ┃     F5    ┃    F6     ┃    F11    ┃   ┃           ┃    GUI    ┃   SHFT    ┃    CTRL   ┃    OPT    ┃
// ┏━━━━━━━━━━━╋━━━━━━━━━━━╋━━━━━━━━━━━╋━━━━━━━━━━━╋━━━━━━━━━━━╋━━━━━━━━━━━┫   ┣━━━━━━━━━━━╋━━━━━━━━━━━╋━━━━━━━━━━━╋━━━━━━━━━━━╋━━━━━━━━━━━╋━━━━━━━━━━━┓
// ┃    ESC    ┃           ┃    F1     ┃     F2    ┃    F3     ┃    F10    ┃   ┃           ┃           ┃           ┃           ┃           ┃    TAB    ┃
// ┗━━━━━━━━━━━┻━━━━━━━━━━━┻━━━━━━━━━━━╋━━━━━━━━━━━╋━━━━━━━━━━━╋━━━━━━━━━━━┫   ┣━━━━━━━━━━━╋━━━━━━━━━━━╋━━━━━━━━━━━╋━━━━━━━━━━━┻━━━━━━━━━━━┻━━━━━━━━━━━┛
//                                     ┃           ┃           ┃           ┃   ┃           ┃           ┃           ┃
//                                     ┗━━━━━━━━━━━┻━━━━━━━━━━━┻━━━━━━━━━━━┛   ┗━━━━━━━━━━━┻━━━━━━━━━━━┻━━━━━━━━━━━┛
 bindings = <
// ╷           ╷           ╷           ╷           ╷           ╷           ╷   ╷           ╷           ╷           ╷           ╷           ╷           ╷

                &none       &none       &none       &none       &none           &none       &none       &none       &none         &none
                &none       &none       &none       &none       &none           &none       &none       &none       &none         &none
                &none       &none       &none       &none       &none           &none       &none       &none       &none         &none
                                        &none       &none       &none           &none       &none       &none
                        >;
                };
        };
};


